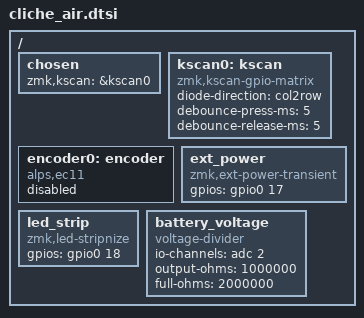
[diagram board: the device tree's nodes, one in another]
 / {
    chosen {
        /* default kscan handle (will be overridden by per-shield if needed) */
        zmk,kscan = &kscan0;
    };

    /* ---------------------------
     * Keyscan controller (common)
     * ---------------------------
     * Per-side overlays must supply row-gpios and col-gpios for &kscan0.
     * Example (in cliche_air_l.dtsi):
     *   &kscan0 {
     *     row-gpios = <&gpio0 2 (GPIO_ACTIVE_HIGH | GPIO_PULL_DOWN)>, ...;
     *     col-gpios = <&gpio0 7 (GPIO_ACTIVE_HIGH | GPIO_PULL_UP)>, ...;
     *   };
     */
    kscan0: kscan {
        compatible = "zmk,kscan-gpio-matrix";
        diode-direction = "col2row";
        /* sensible defaults for debouncing (can be tuned) */
        debounce-press-ms = <5>;
        debounce-release-ms = <5>;
        status = "okay";
        /* row-gpios / col-gpios: intentionally left to per-overlay */
    };

    /* ---------------------------
     * Rotary encoder (common)
     * ---------------------------
     * Disabled by default. Enable in overlay by setting status = "okay"
     * and providing a-gpios / b-gpios.
     */
    encoder0: encoder {
        compatible = "alps,ec11";
        status = "disabled"; /* enable in cliche_air_l.dtsi if present */
    };

    /* ---------------------------
     * External power / LED VCC control
     * ---------------------------
     * This is the node the ext_power_transient driver binds to.
     * Override gpios in overlay if your board uses different pin.
     */
    ext_power: ext_power {
        compatible = "zmk,ext-power-transient";
        /* default: P0.17 as example (override per board if different) */
        gpios = <&gpio0 17 GPIO_ACTIVE_HIGH>;
        status = "okay";
    };

    /* ---------------------------
     * LED data / strip node
     * ---------------------------
     * The led_stripnize driver will use this node. Override gpios as needed.
     */
    led_strip: led_strip {
        compatible = "zmk,led-stripnize";
        /* default data pin example: P0.18 (override in overlays if necessary) */
        gpios = <&gpio0 18 GPIO_ACTIVE_HIGH>;
        status = "okay";
    };

    /* ---------------------------
     * Battery voltage measurement (voltage-divider)
     * ---------------------------
     * Provide a sensible default ADC channel here but allow per-side override.
     * - io-channels: phandle to ADC controller + channel index
     * - output-ohms / full-ohms: divider ratio (example: 1M / 1M)
     */
    battery_voltage: battery_voltage {
        compatible = "voltage-divider";
        io-channels = <&adc 2>; /* default ADC channel (override in overlays) */
        output-ohms = <1000000>; /* upper resistor (ohms) */
        full-ohms   = <2000000>; /* upper + lower (ohms) */
        status = "okay";
    };
};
